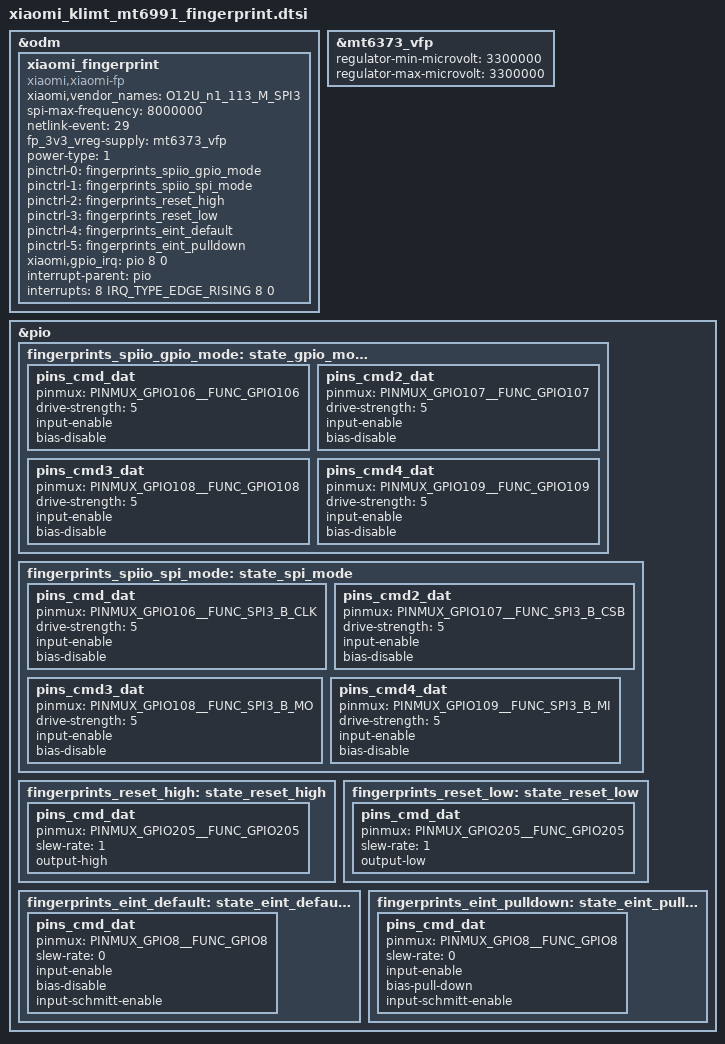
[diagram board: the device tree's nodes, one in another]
// SPDX-License-Identifier: (GPL-2.0 OR MIT)
/*
 * Copyright (C) 2024 MediaTek Inc.
 */

/* fingerprint start */

&odm {
	xiaomi_fingerprint: xiaomi_fingerprint {
		compatible = "xiaomi,xiaomi-fp";
		xiaomi,vendor_names = "O12U_n1_113_M_SPI3";
		spi-max-frequency = <8000000>;
		netlink-event = <29>;
		fp_3v3_vreg-supply = <&mt6373_vfp>;
		power-type = <1>;
		pinctrl-names = "spiio_gpio_mode", "spiio_spi_mode", "reset_high", "reset_low", "eint_default", "eint_pulldown";
		pinctrl-0 = <&fingerprints_spiio_gpio_mode>;
		pinctrl-1 = <&fingerprints_spiio_spi_mode>;
		pinctrl-2 = <&fingerprints_reset_high>;
		pinctrl-3 = <&fingerprints_reset_low>;
		pinctrl-4 = <&fingerprints_eint_default>;
		pinctrl-5 = <&fingerprints_eint_pulldown>;
		xiaomi,gpio_irq = <&pio 8 0>;
		interrupt-parent = <&pio>;
		interrupts = <8 IRQ_TYPE_EDGE_RISING 8 0>;
		status = "okay";
	};
};

&mt6373_vfp {
	regulator-min-microvolt = <3300000>;
	regulator-max-microvolt = <3300000>;
};

&pio {
	fingerprints_spiio_gpio_mode: state_gpio_mode {
		pins_cmd_dat {
			pinmux = <PINMUX_GPIO106__FUNC_GPIO106>;
			drive-strength = <5>;
			input-enable;
			bias-disable;
		};
		pins_cmd2_dat {
			pinmux = <PINMUX_GPIO107__FUNC_GPIO107>;
			drive-strength = <5>;
			input-enable;
			bias-disable;
		};
		pins_cmd3_dat {
			pinmux = <PINMUX_GPIO108__FUNC_GPIO108>;
			drive-strength = <5>;
			input-enable;
			bias-disable;
		};
		pins_cmd4_dat {
			pinmux = <PINMUX_GPIO109__FUNC_GPIO109>;
			drive-strength = <5>;
			input-enable;
			bias-disable;
		};
	};
	fingerprints_spiio_spi_mode: state_spi_mode {
		pins_cmd_dat {
			pinmux = <PINMUX_GPIO106__FUNC_SPI3_B_CLK>;
			drive-strength = <5>;
			input-enable;
			bias-disable;
		};
		pins_cmd2_dat {
			pinmux = <PINMUX_GPIO107__FUNC_SPI3_B_CSB>;
			drive-strength = <5>;
			input-enable;
			bias-disable;
		};
		pins_cmd3_dat {
			pinmux = <PINMUX_GPIO108__FUNC_SPI3_B_MO>;
			drive-strength = <5>;
			input-enable;
			bias-disable;
		};
		pins_cmd4_dat {
			pinmux = <PINMUX_GPIO109__FUNC_SPI3_B_MI>;
			drive-strength = <5>;
			input-enable;
			bias-disable;
		};
	};

	fingerprints_reset_high: state_reset_high {
		pins_cmd_dat {
			pinmux = <PINMUX_GPIO205__FUNC_GPIO205>;
			slew-rate = <1>;
			output-high;
		};
	};
	fingerprints_reset_low: state_reset_low {
		pins_cmd_dat {
			pinmux = <PINMUX_GPIO205__FUNC_GPIO205>;
			slew-rate = <1>;
			output-low;
		};
	};
	fingerprints_eint_default: state_eint_default {
		pins_cmd_dat {
			pinmux = <PINMUX_GPIO8__FUNC_GPIO8>;
			slew-rate = <0>;
			input-enable;
			bias-disable;
			input-schmitt-enable;
		};
	};
	fingerprints_eint_pulldown: state_eint_pulldown {
		pins_cmd_dat {
			pinmux = <PINMUX_GPIO8__FUNC_GPIO8>;
			slew-rate = <0>;
			input-enable;
			bias-pull-down;
			input-schmitt-enable;
		};
	};
};

/* fingerprint end */
